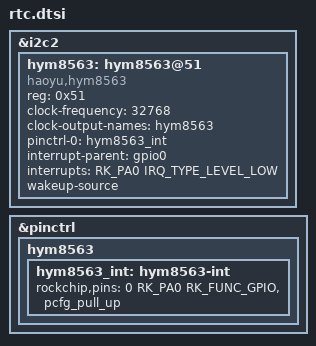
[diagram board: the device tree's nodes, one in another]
&i2c2 {
	status = "okay";

	hym8563: hym8563@51 {
		compatible = "haoyu,hym8563";
		reg = <0x51>;
		#clock-cells = <0>;
		clock-frequency = <32768>;
		clock-output-names = "hym8563";
		pinctrl-names = "default";
		pinctrl-0 = <&hym8563_int>;
		interrupt-parent = <&gpio0>;
		interrupts = <RK_PA0 IRQ_TYPE_LEVEL_LOW>;
		wakeup-source;
	};
};

&pinctrl {
	hym8563 {
		hym8563_int: hym8563-int {
			rockchip,pins = <0 RK_PA0 RK_FUNC_GPIO &pcfg_pull_up>;
		};
	};
};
